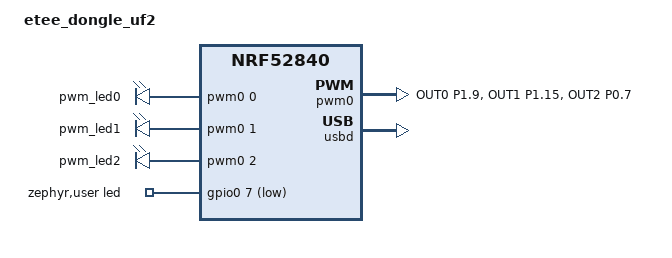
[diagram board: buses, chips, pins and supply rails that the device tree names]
// Copyright (c) 2024 Nordic Semiconductor ASA
// SPDX-License-Identifier: Apache-2.0

/dts-v1/;
#include <nordic/nrf52840_qiaa.dtsi>

//move to dtsi?
&pinctrl {
	pwm0_default: pwm0_default {
		group1 {
			psels = <NRF_PSEL(PWM_OUT0, 1, 9)>,
				<NRF_PSEL(PWM_OUT1, 1, 15)>,
				<NRF_PSEL(PWM_OUT2, 0, 7)>;
			nordic,drive-mode = <NRF_DRIVE_D0S1>;
			nordic,invert;
		};
	};

	pwm0_sleep: pwm0_sleep {
		group1 {
			psels = <NRF_PSEL(PWM_OUT0, 1, 9)>,
				<NRF_PSEL(PWM_OUT1, 1, 15)>,
				<NRF_PSEL(PWM_OUT2, 0, 7)>;
			low-power-enable;
		};
	};
};
//end

/ {
	model = "etee_dongle_uf2";
	compatible = "etee_dongle_uf2";

	chosen {
		zephyr,sram = &sram0;
		zephyr,flash = &flash0;
		zephyr,console = &cdc_acm_uart0;
		zephyr,shell-uart = &cdc_acm_uart0;
	};

	pwmleds {
		compatible = "pwm-leds";
		pwm_led0: pwm_led_0 {
			pwms = <&pwm0 0 PWM_MSEC(1) PWM_POLARITY_INVERTED>;
		};
		pwm_led1: pwm_led_1 {
			pwms = <&pwm0 1 PWM_MSEC(1) PWM_POLARITY_INVERTED>;
		};
		pwm_led2: pwm_led_2 {
			pwms = <&pwm0 2 PWM_MSEC(1) PWM_POLARITY_INVERTED>;
		};
	};

	aliases {
		pwm-led0 = &pwm_led0;
		pwm-led1 = &pwm_led1;
		pwm-led2 = &pwm_led2;
	};

	zephyr,user {
		led-gpios = <&gpio0 7 (GPIO_ACTIVE_LOW | GPIO_OPEN_DRAIN)>;
		// red 1.09, green 1.15, blue 0.07
	};
};

&reg1 {
	regulator-initial-mode = <NRF5X_REG_MODE_DCDC>;
};

&gpio0 {
	status = "okay";
};

&gpiote {
	status = "okay";
};

&pwm0 {
	status = "okay";
	pinctrl-0 = <&pwm0_default>;
	pinctrl-1 = <&pwm0_sleep>;
	pinctrl-names = "default", "sleep";
};

zephyr_udc0: &usbd {
	compatible = "nordic,nrf-usbd";
	status = "okay";
	cdc_acm_uart0: cdc_acm_uart0 {
		compatible = "zephyr,cdc-acm-uart";
	};
};

&cryptocell {
	status = "disabled";
};

&nfct {
	status = "disabled";
};
